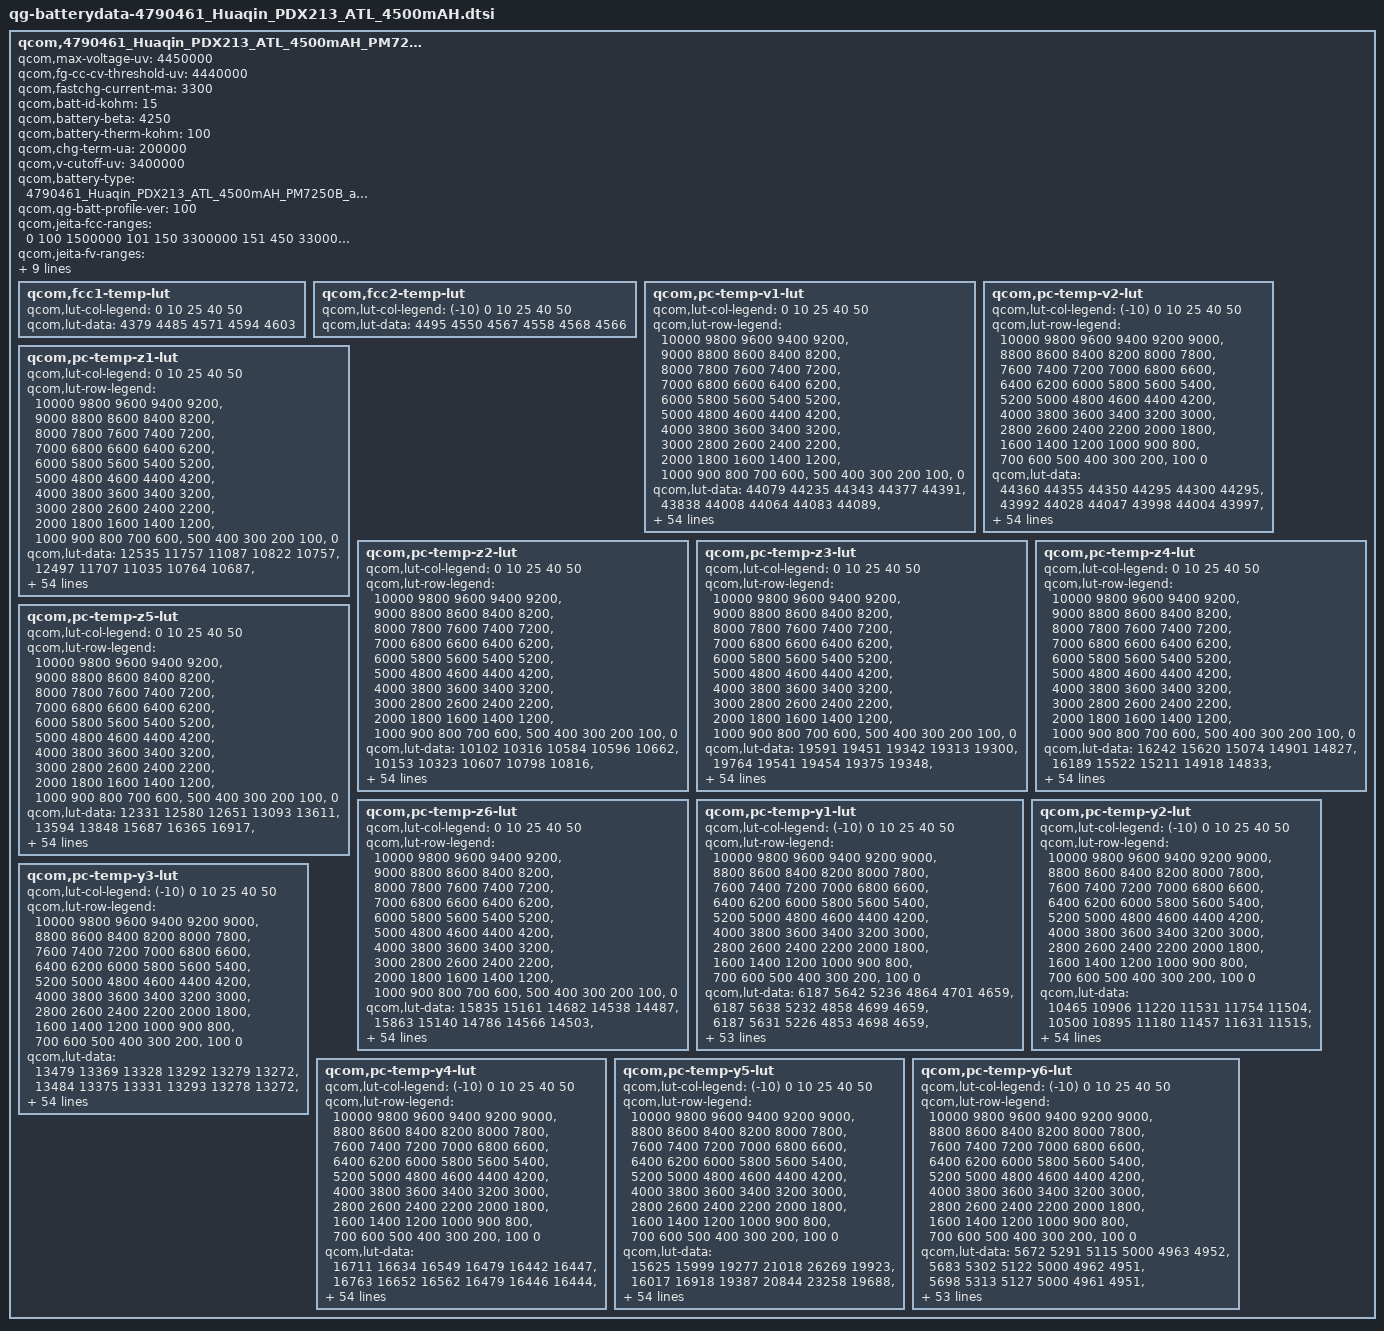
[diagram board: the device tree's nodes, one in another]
qcom,4790461_Huaqin_PDX213_ATL_4500mAH_PM7250B {
	/* 4790461_Huaqin_PDX213_ATL_4500mAH_PM7250B_averaged_MasterSlave_Sep18th2020 */
	qcom,max-voltage-uv = <4450000>;
	qcom,fg-cc-cv-threshold-uv = <4440000>;
	qcom,fastchg-current-ma = <3300>;
	qcom,batt-id-kohm = <15>;
	qcom,battery-beta = <4250>;
	qcom,battery-therm-kohm = <100>;
	qcom,chg-term-ua = <200000>;
	qcom,v-cutoff-uv = <3400000>;
	qcom,battery-type = "4790461_Huaqin_PDX213_ATL_4500mAH_PM7250B_averaged_MasterSlave_Sep18th2020";
	qcom,qg-batt-profile-ver = <100>;

	qcom,jeita-fcc-ranges = <0  100  1500000
				101 150  3300000
				151 450  3300000
				451 550  1000000>;

	qcom,jeita-fv-ranges = <0   100  4400000
				101 150  4400000
				151 450  4450000
				451 550  4100000>;

	qcom,step-chg-ranges = <3500000  4000000  3300000
				4000001  4100000  3300000
				4100001  4450000  1500000>;

	qcom,ocv-based-step-chg;

	/* COOL = 0 degc, WARM = 55 degC */
	qcom,jeita-soft-thresholds = <0x58CD 0x181D>;
	/* COLD = 0 degC, HOT = 55 degC*/
	qcom,jeita-hard-thresholds = <0x58CD 0x181D>;
	/* COOL hys = 5 degC, WARM hys = 50 degC */
	qcom,jeita-soft-hys-thresholds = <0x5314 0x1C22>;
	qcom,jeita-soft-fcc-ua = <1500000 900000>;
	qcom,jeita-soft-fv-uv = <4400000 4100000>;

	qcom,fcc1-temp-lut {
		qcom,lut-col-legend = <0 10 25 40 50>;
		qcom,lut-data = <4379 4485 4571 4594 4603>;
	};

	qcom,fcc2-temp-lut {
		qcom,lut-col-legend = <(-10) 0 10 25 40 50>;
		qcom,lut-data = <4495 4550 4567 4558 4568 4566>;
	};

	qcom,pc-temp-v1-lut {
		qcom,lut-col-legend = <0 10 25 40 50>;
		qcom,lut-row-legend = <10000 9800 9600 9400 9200>,
			<9000 8800 8600 8400 8200>,
			<8000 7800 7600 7400 7200>,
			<7000 6800 6600 6400 6200>,
			<6000 5800 5600 5400 5200>,
			<5000 4800 4600 4400 4200>,
			<4000 3800 3600 3400 3200>,
			<3000 2800 2600 2400 2200>,
			<2000 1800 1600 1400 1200>,
			<1000 900 800 700 600>,
			<500 400 300 200 100>,
			<0>;
		qcom,lut-data = <44079 44235 44343 44377 44391>,
			<43838 44008 44064 44083 44089>,
			<43608 43779 43841 43852 43856>,
			<43384 43552 43628 43640 43643>,
			<43154 43325 43403 43420 43425>,
			<42913 43092 43173 43195 43205>,
			<42669 42850 42937 42965 42978>,
			<42431 42604 42696 42726 42740>,
			<42195 42361 42451 42483 42497>,
			<41963 42118 42207 42240 42255>,
			<41733 41880 41963 41998 42016>,
			<41508 41648 41724 41759 41779>,
			<41291 41422 41489 41523 41545>,
			<41085 41203 41259 41291 41315>,
			<40880 40989 41038 41069 41091>,
			<40673 40781 40826 40854 40873>,
			<40468 40576 40621 40646 40663>,
			<40281 40380 40422 40444 40461>,
			<40107 40201 40233 40252 40268>,
			<39943 40039 40063 40076 40090>,
			<39787 39871 39897 39909 39921>,
			<39638 39698 39705 39714 39730>,
			<39477 39513 39479 39467 39491>,
			<39291 39285 39258 39234 39261>,
			<39104 39001 39045 39051 39077>,
			<38934 38801 38856 38895 38918>,
			<38773 38709 38736 38768 38783>,
			<38653 38643 38651 38665 38667>,
			<38572 38573 38570 38569 38562>,
			<38510 38504 38488 38472 38462>,
			<38456 38439 38411 38381 38371>,
			<38410 38373 38338 38301 38288>,
			<38367 38312 38268 38229 38214>,
			<38322 38259 38207 38164 38144>,
			<38277 38213 38158 38106 38081>,
			<38239 38170 38113 38052 38020>,
			<38207 38133 38068 37997 37956>,
			<38171 38094 38024 37942 37889>,
			<38114 38036 37966 37876 37814>,
			<38033 37951 37883 37794 37727>,
			<37936 37849 37782 37696 37628>,
			<37812 37733 37667 37584 37512>,
			<37668 37595 37531 37452 37375>,
			<37499 37427 37368 37290 37215>,
			<37334 37257 37206 37136 37066>,
			<37226 37140 37088 37028 36968>,
			<37180 37104 37060 37001 36942>,
			<37145 37084 37039 36987 36925>,
			<37112 37064 37023 36969 36908>,
			<37077 37034 36995 36940 36876>,
			<36993 36927 36856 36772 36681>,
			<36637 36528 36456 36361 36265>,
			<36082 35960 35893 35797 35699>,
			<35317 35170 35126 35028 34929>,
			<33982 33856 33940 33843 33745>,
			<30000 30000 30000 30000 30000>;
	};

	qcom,pc-temp-v2-lut {
		qcom,lut-col-legend = <(-10) 0 10 25 40 50>;
		qcom,lut-row-legend = <10000 9800 9600 9400 9200 9000>,
			<8800 8600 8400 8200 8000 7800>,
			<7600 7400 7200 7000 6800 6600>,
			<6400 6200 6000 5800 5600 5400>,
			<5200 5000 4800 4600 4400 4200>,
			<4000 3800 3600 3400 3200 3000>,
			<2800 2600 2400 2200 2000 1800>,
			<1600 1400 1200 1000 900 800>,
			<700 600 500 400 300 200>,
			<100 0>;
		qcom,lut-data = <44360 44355 44350 44295 44300 44295>,
			<43992 44028 44047 43998 44004 43997>,
			<43666 43732 43770 43724 43732 43724>,
			<43391 43476 43523 43476 43485 43477>,
			<43159 43256 43306 43255 43265 43259>,
			<42933 43033 43085 43031 43042 43038>,
			<42696 42792 42846 42792 42807 42803>,
			<42458 42546 42602 42549 42568 42565>,
			<42221 42301 42359 42307 42328 42325>,
			<41984 42054 42116 42065 42086 42083>,
			<41739 41816 41875 41826 41847 41845>,
			<41459 41587 41635 41589 41610 41610>,
			<41179 41364 41400 41358 41378 41380>,
			<40977 41149 41173 41131 41150 41153>,
			<40839 40939 40953 40911 40928 40932>,
			<40672 40726 40742 40698 40714 40717>,
			<40353 40509 40543 40491 40508 40510>,
			<39967 40283 40344 40292 40309 40309>,
			<39711 40032 40130 40109 40122 40122>,
			<39537 39758 39906 39935 39942 39943>,
			<39369 39513 39676 39742 39756 39760>,
			<39175 39302 39427 39509 39561 39571>,
			<38980 39110 39194 39273 39359 39375>,
			<38791 38932 39002 39061 39135 39151>,
			<38604 38768 38834 38862 38904 38915>,
			<38442 38619 38685 38704 38733 38742>,
			<38310 38485 38553 38578 38609 38617>,
			<38199 38359 38435 38468 38502 38510>,
			<38118 38230 38324 38364 38399 38407>,
			<38058 38103 38221 38266 38303 38312>,
			<38003 38011 38130 38178 38216 38224>,
			<37948 37943 38047 38098 38138 38144>,
			<37894 37889 37970 38024 38065 38069>,
			<37836 37845 37889 37959 38000 38002>,
			<37777 37809 37815 37900 37937 37937>,
			<37714 37771 37765 37839 37860 37850>,
			<37646 37733 37732 37776 37768 37733>,
			<37574 37690 37694 37707 37671 37619>,
			<37495 37634 37644 37628 37575 37519>,
			<37408 37564 37582 37540 37477 37423>,
			<37317 37472 37496 37449 37384 37329>,
			<37223 37343 37378 37352 37290 37235>,
			<37131 37198 37245 37236 37175 37118>,
			<37045 37036 37092 37096 37037 36978>,
			<36956 36886 36920 36941 36893 36839>,
			<36868 36782 36830 36876 36849 36799>,
			<36815 36740 36805 36866 36840 36786>,
			<36762 36703 36776 36849 36823 36772>,
			<36706 36667 36732 36828 36799 36753>,
			<36650 36607 36659 36778 36753 36689>,
			<36574 36463 36454 36603 36520 36415>,
			<36418 36090 35998 36152 36036 35920>,
			<36067 35442 35321 35527 35397 35268>,
			<35446 34451 34375 34677 34510 34359>,
			<34469 32921 32908 33453 33255 33082>,
			<32805 30344 29538 29120 29530 29563>;
	};

	qcom,pc-temp-z1-lut {
		qcom,lut-col-legend = <0 10 25 40 50>;
		qcom,lut-row-legend = <10000 9800 9600 9400 9200>,
			<9000 8800 8600 8400 8200>,
			<8000 7800 7600 7400 7200>,
			<7000 6800 6600 6400 6200>,
			<6000 5800 5600 5400 5200>,
			<5000 4800 4600 4400 4200>,
			<4000 3800 3600 3400 3200>,
			<3000 2800 2600 2400 2200>,
			<2000 1800 1600 1400 1200>,
			<1000 900 800 700 600>,
			<500 400 300 200 100>,
			<0>;
		qcom,lut-data = <12535 11757 11087 10822 10757>,
			<12497 11707 11035 10764 10687>,
			<12461 11669 11014 10752 10680>,
			<12419 11646 11001 10741 10673>,
			<12384 11626 10990 10734 10670>,
			<12358 11604 10978 10728 10668>,
			<12336 11577 10968 10725 10667>,
			<12314 11550 10957 10722 10666>,
			<12294 11530 10949 10720 10666>,
			<12273 11513 10946 10719 10666>,
			<12251 11504 10944 10718 10665>,
			<12229 11500 10942 10718 10663>,
			<12213 11497 10939 10717 10662>,
			<12199 11494 10937 10716 10662>,
			<12186 11490 10937 10716 10662>,
			<12172 11487 10937 10716 10663>,
			<12158 11482 10937 10717 10663>,
			<12150 11478 10937 10717 10664>,
			<12143 11476 10938 10718 10665>,
			<12140 11477 10939 10718 10666>,
			<12144 11477 10940 10719 10668>,
			<12151 11482 10942 10720 10669>,
			<12153 11488 10946 10722 10666>,
			<12149 11493 10949 10723 10663>,
			<12145 11499 10954 10726 10666>,
			<12150 11505 10959 10730 10675>,
			<12172 11509 10963 10733 10679>,
			<12186 11513 10968 10736 10681>,
			<12189 11516 10972 10739 10682>,
			<12190 11524 10976 10742 10684>,
			<12191 11530 10981 10745 10687>,
			<12194 11535 10986 10748 10688>,
			<12196 11542 10991 10751 10690>,
			<12193 11545 10996 10754 10691>,
			<12191 11549 11000 10757 10693>,
			<12198 11555 11005 10760 10696>,
			<12229 11566 11011 10764 10699>,
			<12262 11582 11019 10767 10703>,
			<12285 11595 11026 10771 10706>,
			<12305 11607 11033 10775 10708>,
			<12320 11617 11040 10779 10709>,
			<12332 11626 11047 10781 10712>,
			<12342 11635 11054 10783 10715>,
			<12350 11647 11060 10785 10716>,
			<12385 11674 11069 10789 10718>,
			<12388 11670 11075 10793 10718>,
			<12393 11668 11076 10791 10718>,
			<12410 11675 11078 10792 10719>,
			<12394 11691 11078 10793 10721>,
			<12391 11683 11084 10795 10720>,
			<12392 11692 11092 10803 10726>,
			<12455 11739 11109 10817 10734>,
			<12466 11741 11129 10827 10744>,
			<12500 11781 11166 10845 10762>,
			<12500 11781 11166 10845 10762>,
			<12500 11781 11166 10845 10762>;
	};

	qcom,pc-temp-z2-lut {
		qcom,lut-col-legend = <0 10 25 40 50>;
		qcom,lut-row-legend = <10000 9800 9600 9400 9200>,
			<9000 8800 8600 8400 8200>,
			<8000 7800 7600 7400 7200>,
			<7000 6800 6600 6400 6200>,
			<6000 5800 5600 5400 5200>,
			<5000 4800 4600 4400 4200>,
			<4000 3800 3600 3400 3200>,
			<3000 2800 2600 2400 2200>,
			<2000 1800 1600 1400 1200>,
			<1000 900 800 700 600>,
			<500 400 300 200 100>,
			<0>;
		qcom,lut-data = <10102 10316 10584 10596 10662>,
			<10153 10323 10607 10798 10816>,
			<10147 10321 10596 10811 10867>,
			<10124 10305 10575 10765 10881>,
			<10111 10281 10535 10721 10856>,
			<10106 10258 10471 10666 10779>,
			<10103 10234 10442 10629 10732>,
			<10100 10216 10436 10623 10751>,
			<10097 10214 10434 10626 10780>,
			<10093 10215 10440 10637 10785>,
			<10090 10216 10457 10655 10780>,
			<10087 10238 10475 10669 10776>,
			<10089 10272 10496 10681 10757>,
			<10100 10293 10517 10691 10727>,
			<10116 10309 10530 10675 10724>,
			<10131 10324 10541 10619 10755>,
			<10149 10341 10554 10595 10775>,
			<10169 10359 10574 10621 10746>,
			<10196 10375 10589 10654 10712>,
			<10219 10390 10597 10669 10724>,
			<10227 10404 10607 10690 10764>,
			<10233 10417 10632 10736 10834>,
			<10241 10429 10696 10904 11049>,
			<10261 10444 10733 11029 11218>,
			<10285 10463 10689 10908 11148>,
			<10308 10472 10623 10691 10996>,
			<10334 10467 10617 10669 10972>,
			<10349 10461 10638 10825 11071>,
			<10356 10462 10663 10927 11141>,
			<10360 10475 10706 10905 11031>,
			<10362 10487 10745 10859 10844>,
			<10362 10495 10734 10816 10772>,
			<10363 10504 10690 10754 10736>,
			<10370 10511 10671 10728 10724>,
			<10381 10517 10673 10762 10779>,
			<10386 10522 10676 10824 10874>,
			<10388 10525 10691 10884 10964>,
			<10391 10529 10728 10953 11065>,
			<10397 10536 10763 11010 11135>,
			<10408 10554 10800 11058 11185>,
			<10418 10565 10828 11094 11214>,
			<10425 10562 10837 11119 11214>,
			<10436 10559 10841 11136 11211>,
			<10468 10571 10845 11126 11217>,
			<10739 10711 10885 11102 11194>,
			<10523 10840 10940 11102 11130>,
			<10501 10833 10927 11050 11135>,
			<10466 10948 10907 11008 11070>,
			<10419 11251 10875 11035 11102>,
			<10368 11339 10875 11033 11215>,
			<10359 11253 11018 11086 10969>,
			<10260 11172 11141 10827 10769>,
			<10039 11005 11032 10734 10689>,
			<9912 10833 11008 10638 10616>,
			<9912 10833 11008 10638 10616>,
			<9912 10833 11008 10638 10616>;
	};

	qcom,pc-temp-z3-lut {
		qcom,lut-col-legend = <0 10 25 40 50>;
		qcom,lut-row-legend = <10000 9800 9600 9400 9200>,
			<9000 8800 8600 8400 8200>,
			<8000 7800 7600 7400 7200>,
			<7000 6800 6600 6400 6200>,
			<6000 5800 5600 5400 5200>,
			<5000 4800 4600 4400 4200>,
			<4000 3800 3600 3400 3200>,
			<3000 2800 2600 2400 2200>,
			<2000 1800 1600 1400 1200>,
			<1000 900 800 700 600>,
			<500 400 300 200 100>,
			<0>;
		qcom,lut-data = <19591 19451 19342 19313 19300>,
			<19764 19541 19454 19375 19348>,
			<19815 19603 19479 19397 19370>,
			<19841 19626 19493 19408 19381>,
			<19852 19638 19501 19416 19386>,
			<19856 19642 19505 19422 19389>,
			<19859 19641 19506 19425 19390>,
			<19854 19640 19495 19418 19389>,
			<19831 19637 19481 19407 19385>,
			<19815 19630 19470 19400 19381>,
			<19811 19621 19460 19394 19374>,
			<19808 19605 19453 19389 19367>,
			<19800 19588 19448 19385 19359>,
			<19781 19578 19443 19380 19351>,
			<19766 19572 19434 19371 19346>,
			<19763 19566 19424 19359 19342>,
			<19761 19558 19420 19353 19340>,
			<19754 19552 19418 19351 19335>,
			<19726 19548 19416 19350 19329>,
			<19703 19546 19413 19348 19325>,
			<19705 19544 19409 19345 19321>,
			<19715 19545 19412 19347 19321>,
			<19722 19547 19430 19362 19333>,
			<19727 19554 19441 19374 19344>,
			<19730 19570 19435 19362 19334>,
			<19731 19579 19424 19339 19313>,
			<19732 19568 19414 19333 19312>,
			<19733 19553 19405 19333 19346>,
			<19728 19549 19401 19335 19371>,
			<19720 19548 19410 19355 19370>,
			<19712 19547 19424 19382 19368>,
			<19703 19552 19433 19385 19364>,
			<19698 19558 19440 19378 19353>,
			<19697 19558 19442 19370 19343>,
			<19696 19553 19435 19364 19335>,
			<19695 19548 19426 19358 19329>,
			<19690 19545 19421 19355 19328>,
			<19683 19542 19418 19351 19327>,
			<19677 19538 19414 19350 19327>,
			<19670 19534 19410 19350 19328>,
			<19661 19528 19407 19349 19329>,
			<19650 19522 19405 19349 19332>,
			<19636 19513 19403 19348 19337>,
			<19616 19503 19397 19347 19337>,
			<19544 19475 19385 19341 19332>,
			<19342 19447 19377 19334 19316>,
			<19332 19444 19372 19333 19313>,
			<19317 19411 19372 19323 19313>,
			<19314 19316 19365 19323 19310>,
			<19308 19302 19364 19319 19305>,
			<19306 19316 19353 19325 19329>,
			<19310 19342 19337 19341 19337>,
			<19318 19316 19349 19346 19338>,
			<19329 19321 19334 19351 19341>,
			<19329 19321 19334 19351 19341>,
			<19329 19321 19334 19351 19341>;
	};

	qcom,pc-temp-z4-lut {
		qcom,lut-col-legend = <0 10 25 40 50>;
		qcom,lut-row-legend = <10000 9800 9600 9400 9200>,
			<9000 8800 8600 8400 8200>,
			<8000 7800 7600 7400 7200>,
			<7000 6800 6600 6400 6200>,
			<6000 5800 5600 5400 5200>,
			<5000 4800 4600 4400 4200>,
			<4000 3800 3600 3400 3200>,
			<3000 2800 2600 2400 2200>,
			<2000 1800 1600 1400 1200>,
			<1000 900 800 700 600>,
			<500 400 300 200 100>,
			<0>;
		qcom,lut-data = <16242 15620 15074 14901 14827>,
			<16189 15522 15211 14918 14833>,
			<16038 15420 15123 14908 14838>,
			<15770 15309 15003 14858 14806>,
			<15555 15184 14935 14820 14779>,
			<15407 15081 14884 14789 14756>,
			<15287 15008 14843 14766 14737>,
			<15201 14949 14808 14751 14723>,
			<15134 14902 14782 14740 14713>,
			<15076 14863 14770 14731 14707>,
			<15018 14836 14762 14723 14703>,
			<14968 14817 14753 14716 14699>,
			<14932 14804 14742 14707 14696>,
			<14906 14794 14733 14699 14692>,
			<14883 14786 14728 14696 14689>,
			<14860 14781 14724 14694 14679>,
			<14839 14781 14719 14691 14672>,
			<14836 14780 14711 14683 14667>,
			<14846 14775 14705 14674 14662>,
			<14856 14756 14699 14667 14658>,
			<14842 14746 14694 14661 14653>,
			<14806 14748 14697 14663 14653>,
			<14793 14755 14717 14695 14682>,
			<14810 14780 14745 14738 14723>,
			<14837 14855 14797 14779 14760>,
			<14864 14897 14848 14816 14794>,
			<14896 14890 14853 14822 14795>,
			<14909 14875 14844 14809 14748>,
			<14906 14860 14832 14791 14705>,
			<14899 14842 14806 14752 14688>,
			<14890 14825 14775 14709 14678>,
			<14878 14808 14752 14693 14672>,
			<14865 14794 14732 14685 14667>,
			<14854 14785 14723 14681 14664>,
			<14845 14779 14722 14679 14663>,
			<14834 14774 14721 14678 14662>,
			<14823 14769 14721 14680 14664>,
			<14812 14764 14722 14686 14672>,
			<14801 14761 14723 14693 14678>,
			<14790 14760 14730 14701 14682>,
			<14779 14757 14737 14706 14684>,
			<14769 14745 14729 14701 14680>,
			<14757 14729 14715 14693 14671>,
			<14737 14717 14710 14693 14673>,
			<14732 14692 14698 14691 14673>,
			<14894 14678 14679 14676 14671>,
			<14901 14673 14671 14669 14666>,
			<14911 14695 14656 14660 14650>,
			<14910 14797 14647 14640 14631>,
			<14910 14807 14640 14636 14628>,
			<14908 14791 14667 14656 14633>,
			<14916 14774 14700 14650 14633>,
			<14918 14811 14687 14646 14633>,
			<14923 14813 14706 14643 14632>,
			<14923 14813 14706 14643 14632>,
			<14923 14813 14706 14643 14632>;
	};

	qcom,pc-temp-z5-lut {
		qcom,lut-col-legend = <0 10 25 40 50>;
		qcom,lut-row-legend = <10000 9800 9600 9400 9200>,
			<9000 8800 8600 8400 8200>,
			<8000 7800 7600 7400 7200>,
			<7000 6800 6600 6400 6200>,
			<6000 5800 5600 5400 5200>,
			<5000 4800 4600 4400 4200>,
			<4000 3800 3600 3400 3200>,
			<3000 2800 2600 2400 2200>,
			<2000 1800 1600 1400 1200>,
			<1000 900 800 700 600>,
			<500 400 300 200 100>,
			<0>;
		qcom,lut-data = <12331 12580 12651 13093 13611>,
			<13594 13848 15687 16365 16917>,
			<14157 14864 16591 17475 18465>,
			<14500 15548 17350 18370 19750>,
			<14891 16037 18038 19234 20605>,
			<15467 16549 18628 20124 21142>,
			<16037 17158 19041 20576 21708>,
			<16392 17808 19373 20631 22749>,
			<16628 18517 19567 20671 23790>,
			<16959 19304 19570 20724 23798>,
			<17822 19882 19543 20744 23094>,
			<18902 20198 19619 20796 22619>,
			<19513 20460 20245 21238 22209>,
			<19907 20818 20740 21703 21592>,
			<20399 21266 20585 21292 21443>,
			<22417 21690 20285 20013 21941>,
			<25449 22052 20351 19563 22420>,
			<26030 22422 21271 20361 22659>,
			<23582 22856 22338 21550 22626>,
			<21394 23455 23034 22508 22513>,
			<22630 24380 23837 23594 22750>,
			<26698 26541 27034 26374 24157>,
			<31065 29861 38416 36433 31204>,
			<36618 34092 45422 43803 36886>,
			<41118 40196 39780 36300 31013>,
			<42030 43147 30149 22108 19010>,
			<42390 37828 25138 17542 16237>,
			<42481 30124 21441 16349 18630>,
			<40584 28122 20092 15943 21400>,
			<37485 27534 20770 18306 23707>,
			<35457 27340 22216 22457 25672>,
			<33763 29263 25203 25015 26331>,
			<32948 32446 30735 26844 26411>,
			<33508 34172 33537 28432 26659>,
			<34544 35313 34255 30206 27669>,
			<34935 35954 34602 31637 28649>,
			<34666 36213 34587 31869 28708>,
			<34473 36336 34466 31207 28524>,
			<35062 36344 34091 30153 28170>,
			<36075 36230 31485 27716 26519>,
			<36297 35917 29124 25501 24947>,
			<34294 34604 28989 25050 25806>,
			<32586 33019 28981 24792 27660>,
			<31957 31873 27075 23746 26525>,
			<27022 33284 26353 22160 24312>,
			<12913 30733 28139 22324 19504>,
			<12654 29402 26855 22693 19341>,
			<12285 19693 29140 21575 21451>,
			<12187 12847 26569 25559 26451>,
			<12093 12439 27527 25743 26433>,
			<12091 12916 20918 20402 27946>,
			<12143 14011 15797 21937 28838>,
			<12123 12720 16665 22568 28628>,
			<12467 12880 14783 23835 29178>,
			<12467 12880 14783 23835 29178>,
			<12467 12880 14783 23835 29178>;
	};

	qcom,pc-temp-z6-lut {
		qcom,lut-col-legend = <0 10 25 40 50>;
		qcom,lut-row-legend = <10000 9800 9600 9400 9200>,
			<9000 8800 8600 8400 8200>,
			<8000 7800 7600 7400 7200>,
			<7000 6800 6600 6400 6200>,
			<6000 5800 5600 5400 5200>,
			<5000 4800 4600 4400 4200>,
			<4000 3800 3600 3400 3200>,
			<3000 2800 2600 2400 2200>,
			<2000 1800 1600 1400 1200>,
			<1000 900 800 700 600>,
			<500 400 300 200 100>,
			<0>;
		qcom,lut-data = <15835 15161 14682 14538 14487>,
			<15863 15140 14786 14566 14503>,
			<15817 15115 14754 14569 14511>,
			<15679 15079 14710 14555 14505>,
			<15563 15020 14684 14543 14498>,
			<15484 14965 14662 14533 14490>,
			<15415 14926 14641 14523 14482>,
			<15355 14892 14618 14512 14475>,
			<15300 14862 14599 14502 14469>,
			<15254 14837 14587 14494 14463>,
			<15216 14815 14578 14487 14458>,
			<15183 14796 14569 14481 14452>,
			<15153 14781 14562 14474 14447>,
			<15124 14770 14554 14468 14441>,
			<15101 14763 14547 14461 14435>,
			<15086 14757 14541 14454 14429>,
			<15075 14751 14535 14449 14424>,
			<15065 14746 14531 14444 14419>,
			<15056 14739 14527 14439 14414>,
			<15048 14731 14523 14435 14410>,
			<15041 14727 14519 14432 14405>,
			<15035 14729 14521 14433 14406>,
			<15034 14735 14540 14457 14426>,
			<15044 14751 14559 14481 14449>,
			<15061 14793 14578 14490 14458>,
			<15076 14816 14595 14496 14464>,
			<15091 14809 14595 14497 14465>,
			<15098 14797 14587 14492 14462>,
			<15095 14788 14580 14486 14458>,
			<15089 14780 14574 14482 14453>,
			<15083 14775 14569 14477 14447>,
			<15074 14772 14565 14472 14441>,
			<15068 14771 14562 14465 14434>,
			<15066 14768 14558 14460 14428>,
			<15065 14764 14554 14455 14423>,
			<15063 14761 14550 14451 14419>,
			<15060 14761 14549 14451 14419>,
			<15057 14760 14549 14453 14422>,
			<15058 14760 14549 14454 14425>,
			<15059 14762 14551 14458 14427>,
			<15060 14763 14553 14461 14429>,
			<15060 14759 14551 14459 14429>,
			<15059 14752 14545 14455 14428>,
			<15054 14748 14541 14455 14428>,
			<15024 14731 14531 14451 14426>,
			<15004 14716 14520 14441 14418>,
			<15003 14712 14515 14438 14414>,
			<15002 14706 14509 14429 14406>,
			<15001 14703 14501 14420 14397>,
			<15003 14704 14500 14417 14393>,
			<15013 14711 14508 14429 14408>,
			<15030 14725 14517 14438 14414>,
			<15049 14737 14523 14441 14418>,
			<15081 14757 14530 14446 14423>,
			<15081 14757 14530 14446 14423>,
			<15081 14757 14530 14446 14423>;
	};

	qcom,pc-temp-y1-lut {
		qcom,lut-col-legend = <(-10) 0 10 25 40 50>;
		qcom,lut-row-legend = <10000 9800 9600 9400 9200 9000>,
			<8800 8600 8400 8200 8000 7800>,
			<7600 7400 7200 7000 6800 6600>,
			<6400 6200 6000 5800 5600 5400>,
			<5200 5000 4800 4600 4400 4200>,
			<4000 3800 3600 3400 3200 3000>,
			<2800 2600 2400 2200 2000 1800>,
			<1600 1400 1200 1000 900 800>,
			<700 600 500 400 300 200>,
			<100 0>;
		qcom,lut-data = <6187 5642 5236 4864 4701 4659>,
			<6187 5638 5232 4858 4699 4659>,
			<6187 5631 5226 4853 4698 4659>,
			<6188 5621 5219 4848 4696 4658>,
			<6189 5614 5212 4843 4695 4658>,
			<6190 5611 5206 4839 4695 4658>,
			<6191 5611 5199 4836 4695 4657>,
			<6191 5610 5193 4834 4695 4656>,
			<6192 5608 5192 4831 4694 4656>,
			<6198 5601 5191 4828 4692 4657>,
			<6203 5598 5191 4826 4690 4657>,
			<6207 5606 5189 4825 4690 4656>,
			<6210 5614 5185 4824 4689 4655>,
			<6207 5612 5182 4824 4689 4656>,
			<6190 5599 5177 4823 4689 4658>,
			<6179 5592 5175 4822 4689 4658>,
			<6186 5601 5173 4822 4690 4657>,
			<6198 5613 5172 4821 4691 4656>,
			<6200 5614 5173 4822 4692 4657>,
			<6198 5615 5176 4824 4691 4659>,
			<6196 5614 5179 4826 4691 4659>,
			<6197 5612 5184 4827 4692 4658>,
			<6198 5610 5188 4829 4692 4657>,
			<6198 5612 5189 4832 4693 4658>,
			<6200 5618 5188 4835 4695 4660>,
			<6201 5621 5189 4838 4696 4661>,
			<6199 5619 5192 4841 4698 4664>,
			<6196 5617 5194 4843 4699 4665>,
			<6200 5624 5196 4847 4700 4665>,
			<6222 5638 5198 4850 4702 4666>,
			<6235 5641 5200 4854 4703 4666>,
			<6220 5626 5203 4857 4706 4668>,
			<6197 5614 5206 4860 4708 4670>,
			<6190 5623 5208 4863 4709 4671>,
			<6192 5640 5210 4867 4711 4673>,
			<6192 5643 5215 4870 4712 4675>,
			<6191 5636 5224 4874 4714 4676>,
			<6191 5630 5232 4876 4715 4677>,
			<6191 5633 5236 4879 4716 4677>,
			<6181 5637 5239 4882 4716 4676>,
			<6173 5636 5239 4883 4718 4677>,
			<6180 5625 5237 4885 4719 4679>,
			<6191 5629 5242 4888 4721 4680>,
			<6201 5650 5253 4892 4723 4681>,
			<6209 5644 5275 4898 4725 4682>,
			<6277 5681 5284 4906 4727 4683>,
			<6290 5673 5285 4908 4727 4685>,
			<6292 5667 5288 4909 4728 4686>,
			<6261 5678 5293 4913 4730 4685>,
			<6319 5697 5299 4916 4730 4686>,
			<6312 5712 5295 4917 4730 4687>,
			<6392 5746 5302 4923 4733 4689>,
			<6497 5809 5324 4943 4740 4695>,
			<6536 5863 5385 4965 4749 4704>,
			<6536 5863 5385 4965 4749 4704>,
			<6536 5863 5385 4965 4749 4704>;
	};

	qcom,pc-temp-y2-lut {
		qcom,lut-col-legend = <(-10) 0 10 25 40 50>;
		qcom,lut-row-legend = <10000 9800 9600 9400 9200 9000>,
			<8800 8600 8400 8200 8000 7800>,
			<7600 7400 7200 7000 6800 6600>,
			<6400 6200 6000 5800 5600 5400>,
			<5200 5000 4800 4600 4400 4200>,
			<4000 3800 3600 3400 3200 3000>,
			<2800 2600 2400 2200 2000 1800>,
			<1600 1400 1200 1000 900 800>,
			<700 600 500 400 300 200>,
			<100 0>;
		qcom,lut-data = <10465 10906 11220 11531 11754 11504>,
			<10500 10895 11180 11457 11631 11515>,
			<10539 10881 11139 11383 11492 11512>,
			<10577 10866 11099 11314 11363 11498>,
			<10609 10850 11059 11255 11269 11475>,
			<10630 10836 11020 11210 11236 11445>,
			<10642 10819 10975 11174 11263 11370>,
			<10650 10805 10936 11148 11297 11286>,
			<10649 10800 10921 11141 11290 11254>,
			<10635 10798 10911 11140 11248 11232>,
			<10626 10797 10908 11140 11226 11224>,
			<10695 10804 10915 11137 11224 11263>,
			<10804 10821 10926 11135 11223 11314>,
			<10822 10857 10938 11143 11231 11336>,
			<10808 10927 10956 11171 11258 11357>,
			<10798 10959 10981 11206 11287 11363>,
			<10811 10958 11041 11268 11314 11351>,
			<10838 10957 11106 11336 11349 11342>,
			<10864 10974 11147 11386 11407 11374>,
			<10895 11024 11179 11428 11493 11470>,
			<10911 11057 11188 11440 11584 11583>,
			<10909 11073 11184 11422 11704 11749>,
			<10904 11085 11181 11404 11783 11864>,
			<10894 11095 11197 11406 11732 11800>,
			<10866 11105 11234 11417 11611 11661>,
			<10815 11111 11260 11433 11557 11624>,
			<10462 11117 11277 11463 11537 11642>,
			<9936 11121 11291 11491 11528 11672>,
			<9781 11118 11307 11514 11568 11717>,
			<9745 11112 11320 11541 11659 11788>,
			<9723 11110 11323 11566 11745 11885>,
			<9707 11114 11318 11601 11836 12038>,
			<9696 11117 11313 11622 11901 12127>,
			<9687 11098 11312 11617 11940 12127>,
			<9681 11047 11312 11606 11968 12115>,
			<9676 11001 11304 11598 11963 12078>,
			<9673 10956 11284 11586 11896 11981>,
			<9670 10906 11260 11581 11846 11928>,
			<9668 10855 11231 11583 11789 11934>,
			<9667 10786 11193 11585 11726 11943>,
			<9665 10565 11134 11568 11728 11929>,
			<9664 9924 11050 11510 11756 11874>,
			<9663 9724 10979 11495 11755 11849>,
			<9662 9695 10892 11491 11718 11841>,
			<9661 9681 10787 11388 11672 11815>,
			<9660 9673 10688 11356 11635 11631>,
			<9659 9669 10645 11373 11539 11568>,
			<9658 9665 10559 11364 11500 11473>,
			<9656 9663 10329 11341 11452 11494>,
			<9654 9660 10089 11319 11499 11565>,
			<9652 9657 9747 11287 11435 11408>,
			<9649 9652 9690 11233 11355 11306>,
			<9648 9649 9663 11090 11268 11267>,
			<9647 9648 9654 10970 11146 11125>,
			<9647 9648 9654 10970 11146 11125>,
			<9647 9648 9654 10970 11146 11125>;
	};

	qcom,pc-temp-y3-lut {
		qcom,lut-col-legend = <(-10) 0 10 25 40 50>;
		qcom,lut-row-legend = <10000 9800 9600 9400 9200 9000>,
			<8800 8600 8400 8200 8000 7800>,
			<7600 7400 7200 7000 6800 6600>,
			<6400 6200 6000 5800 5600 5400>,
			<5200 5000 4800 4600 4400 4200>,
			<4000 3800 3600 3400 3200 3000>,
			<2800 2600 2400 2200 2000 1800>,
			<1600 1400 1200 1000 900 800>,
			<700 600 500 400 300 200>,
			<100 0>;
		qcom,lut-data = <13479 13369 13328 13292 13279 13272>,
			<13484 13375 13331 13293 13278 13272>,
			<13491 13383 13334 13294 13278 13272>,
			<13499 13392 13337 13295 13278 13272>,
			<13506 13399 13340 13295 13278 13273>,
			<13509 13403 13342 13295 13278 13273>,
			<13511 13404 13343 13295 13279 13274>,
			<13512 13405 13344 13296 13281 13275>,
			<13512 13405 13346 13297 13283 13276>,
			<13508 13404 13348 13300 13286 13277>,
			<13502 13402 13348 13302 13287 13278>,
			<13493 13401 13346 13302 13288 13281>,
			<13483 13400 13343 13302 13289 13283>,
			<13475 13400 13343 13303 13289 13284>,
			<13468 13402 13343 13307 13288 13285>,
			<13461 13403 13344 13309 13289 13285>,
			<13453 13398 13344 13307 13291 13284>,
			<13444 13390 13345 13306 13293 13284>,
			<13440 13384 13344 13304 13293 13284>,
			<13437 13379 13343 13304 13292 13286>,
			<13434 13374 13341 13303 13291 13286>,
			<13428 13370 13335 13301 13290 13285>,
			<13420 13366 13329 13300 13288 13284>,
			<13414 13362 13325 13297 13284 13280>,
			<13410 13359 13322 13293 13279 13273>,
			<13404 13356 13321 13291 13277 13272>,
			<13390 13354 13320 13291 13277 13272>,
			<13372 13351 13319 13291 13278 13273>,
			<13371 13347 13318 13291 13277 13273>,
			<13385 13340 13316 13290 13275 13273>,
			<13402 13336 13316 13289 13275 13273>,
			<13417 13334 13317 13290 13275 13273>,
			<13434 13332 13317 13290 13276 13273>,
			<13454 13336 13315 13290 13278 13274>,
			<13481 13344 13313 13290 13279 13274>,
			<13513 13351 13313 13290 13279 13274>,
			<13550 13357 13317 13291 13278 13272>,
			<13595 13362 13320 13291 13277 13271>,
			<13645 13366 13323 13290 13276 13272>,
			<13703 13370 13325 13289 13275 13272>,
			<13766 13378 13326 13289 13275 13273>,
			<13833 13394 13328 13289 13276 13274>,
			<13908 13413 13329 13289 13277 13275>,
			<13996 13438 13331 13290 13277 13275>,
			<14100 13475 13331 13289 13273 13270>,
			<14159 13512 13332 13289 13276 13274>,
			<14238 13568 13339 13294 13281 13275>,
			<14355 13650 13347 13296 13283 13281>,
			<14511 13774 13354 13302 13287 13284>,
			<14795 13956 13371 13307 13291 13284>,
			<15632 14286 13407 13307 13286 13280>,
			<17658 15259 13490 13304 13284 13280>,
			<23753 19034 13756 13309 13286 13281>,
			<47602 37611 15114 13318 13291 13285>,
			<47602 37611 15114 13318 13291 13285>,
			<47602 37611 15114 13318 13291 13285>;
	};

	qcom,pc-temp-y4-lut {
		qcom,lut-col-legend = <(-10) 0 10 25 40 50>;
		qcom,lut-row-legend = <10000 9800 9600 9400 9200 9000>,
			<8800 8600 8400 8200 8000 7800>,
			<7600 7400 7200 7000 6800 6600>,
			<6400 6200 6000 5800 5600 5400>,
			<5200 5000 4800 4600 4400 4200>,
			<4000 3800 3600 3400 3200 3000>,
			<2800 2600 2400 2200 2000 1800>,
			<1600 1400 1200 1000 900 800>,
			<700 600 500 400 300 200>,
			<100 0>;
		qcom,lut-data = <16711 16634 16549 16479 16442 16447>,
			<16763 16652 16562 16479 16446 16444>,
			<16842 16687 16577 16480 16448 16443>,
			<16929 16727 16590 16481 16450 16442>,
			<17001 16760 16600 16482 16451 16441>,
			<17037 16773 16604 16483 16451 16441>,
			<17045 16773 16601 16486 16451 16442>,
			<17050 16773 16597 16489 16450 16443>,
			<17056 16775 16597 16490 16450 16444>,
			<17065 16780 16598 16490 16451 16447>,
			<17070 16788 16600 16491 16453 16448>,
			<17057 16802 16611 16499 16457 16449>,
			<17037 16821 16629 16509 16463 16449>,
			<17050 16841 16644 16516 16470 16451>,
			<17140 16863 16660 16521 16478 16456>,
			<17199 16873 16679 16529 16485 16463>,
			<17083 16875 16712 16548 16490 16471>,
			<16897 16876 16736 16572 16497 16479>,
			<16850 16849 16730 16601 16511 16488>,
			<16845 16765 16705 16634 16534 16499>,
			<16838 16708 16674 16643 16547 16510>,
			<16813 16681 16625 16609 16555 16526>,
			<16772 16661 16580 16561 16559 16536>,
			<16727 16642 16558 16522 16530 16512>,
			<16666 16626 16543 16486 16470 16461>,
			<16632 16612 16535 16476 16453 16446>,
			<16661 16600 16531 16477 16455 16447>,
			<16710 16589 16529 16478 16457 16449>,
			<16723 16569 16529 16482 16463 16453>,
			<16726 16545 16530 16490 16475 16462>,
			<16728 16539 16530 16498 16485 16470>,
			<16734 16547 16529 16505 16496 16479>,
			<16742 16558 16527 16513 16504 16488>,
			<16747 16567 16521 16524 16512 16498>,
			<16753 16577 16513 16534 16517 16506>,
			<16757 16592 16514 16536 16516 16504>,
			<16759 16616 16529 16530 16501 16483>,
			<16760 16641 16547 16521 16487 16468>,
			<16760 16661 16567 16505 16474 16462>,
			<16757 16679 16584 16487 16465 16458>,
			<16756 16693 16587 16485 16465 16458>,
			<16760 16705 16587 16489 16466 16458>,
			<16768 16701 16590 16492 16465 16457>,
			<16778 16677 16592 16494 16462 16452>,
			<16791 16658 16563 16474 16445 16436>,
			<16761 16650 16557 16472 16448 16441>,
			<16764 16660 16572 16480 16453 16449>,
			<16774 16679 16594 16496 16463 16453>,
			<16793 16704 16635 16511 16479 16486>,
			<16828 16745 16687 16535 16521 16532>,
			<16999 16781 16727 16536 16495 16477>,
			<17362 16870 16722 16506 16454 16447>,
			<18460 17894 16766 16518 16457 16453>,
			<25601 29728 17319 16556 16482 16476>,
			<25601 29728 17319 16556 16482 16476>,
			<25601 29728 17319 16556 16482 16476>;
	};

	qcom,pc-temp-y5-lut {
		qcom,lut-col-legend = <(-10) 0 10 25 40 50>;
		qcom,lut-row-legend = <10000 9800 9600 9400 9200 9000>,
			<8800 8600 8400 8200 8000 7800>,
			<7600 7400 7200 7000 6800 6600>,
			<6400 6200 6000 5800 5600 5400>,
			<5200 5000 4800 4600 4400 4200>,
			<4000 3800 3600 3400 3200 3000>,
			<2800 2600 2400 2200 2000 1800>,
			<1600 1400 1200 1000 900 800>,
			<700 600 500 400 300 200>,
			<100 0>;
		qcom,lut-data = <15625 15999 19277 21018 26269 19923>,
			<16017 16918 19387 20844 23258 19688>,
			<16429 17624 19336 20052 20610 19348>,
			<16849 18121 19182 18971 18495 18966>,
			<17264 18413 18985 17921 17083 18611>,
			<17662 18502 18802 17227 16548 18347>,
			<18134 18332 18459 16495 17129 18143>,
			<18548 18003 18011 15800 17993 17923>,
			<18629 17632 17702 15806 18279 17610>,
			<18596 17137 17446 16198 18795 17177>,
			<18518 16921 17068 16301 18849 17024>,
			<17751 17010 16109 15681 18198 18132>,
			<16625 17185 15200 15022 17329 19424>,
			<16859 17374 15096 15023 16492 19274>,
			<19328 17632 15230 15236 15612 18286>,
			<20963 18107 15498 15310 15325 17306>,
			<20356 20259 16395 14828 15530 16294>,
			<19388 22433 17778 14309 15740 15547>,
			<19498 22463 19772 14485 15480 15377>,
			<21139 22021 22323 15314 14788 15289>,
			<22332 21855 23091 16666 14814 15434>,
			<22514 22176 22741 20422 17925 17434>,
			<22583 22545 22308 23538 20681 19330>,
			<22477 22623 21980 23021 20568 19318>,
			<22107 22643 21649 21515 20050 18874>,
			<21514 22748 21537 20906 19660 18791>,
			<18244 23130 21743 20840 19414 18728>,
			<13516 23437 21891 20761 19082 18515>,
			<12551 22447 21694 20239 17967 17937>,
			<12704 19911 21454 19479 16427 17119>,
			<12876 18092 21769 19327 16125 16885>,
			<13044 16692 23767 19556 16455 16803>,
			<13232 15922 25033 19871 16973 16768>,
			<13372 16522 23455 20269 18057 17057>,
			<13578 17994 21074 20891 19477 17594>,
			<13759 19138 20827 21771 20051 17903>,
			<13981 20135 21587 23225 20130 18102>,
			<14239 20672 22029 24053 20035 18327>,
			<14279 20700 21663 23362 19525 18756>,
			<14159 20692 20938 21904 18969 19338>,
			<13977 20143 20148 20594 19004 20121>,
			<13595 17332 19208 19336 19166 21367>,
			<13207 15721 18602 18878 19104 22053>,
			<13203 14921 18309 18707 19019 22135>,
			<13137 14240 18311 20380 19257 20607>,
			<13470 13850 17926 18749 17963 18368>,
			<13446 13629 18048 19888 18908 16988>,
			<13484 13628 17522 17982 17278 20228>,
			<13431 13910 15893 18169 19203 22254>,
			<13382 13965 15082 18532 20814 19006>,
			<12535 14004 14177 19563 19096 19630>,
			<11342 12900 14348 20445 21537 23296>,
			<9900 10316 13859 21319 22893 22877>,
			<9079 9055 11936 22217 25874 26587>,
			<9079 9055 11936 22217 25874 26587>,
			<9079 9055 11936 22217 25874 26587>;
	};

	qcom,pc-temp-y6-lut {
		qcom,lut-col-legend = <(-10) 0 10 25 40 50>;
		qcom,lut-row-legend = <10000 9800 9600 9400 9200 9000>,
			<8800 8600 8400 8200 8000 7800>,
			<7600 7400 7200 7000 6800 6600>,
			<6400 6200 6000 5800 5600 5400>,
			<5200 5000 4800 4600 4400 4200>,
			<4000 3800 3600 3400 3200 3000>,
			<2800 2600 2400 2200 2000 1800>,
			<1600 1400 1200 1000 900 800>,
			<700 600 500 400 300 200>,
			<100 0>;
		qcom,lut-data = <5672 5291 5115 5000 4963 4952>,
			<5683 5302 5122 5000 4962 4951>,
			<5698 5313 5127 5000 4961 4951>,
			<5713 5323 5130 5000 4961 4951>,
			<5724 5330 5132 5001 4962 4952>,
			<5728 5333 5133 5001 4962 4953>,
			<5727 5331 5131 5001 4963 4953>,
			<5724 5328 5128 5002 4965 4954>,
			<5722 5325 5128 5003 4966 4955>,
			<5718 5322 5127 5005 4968 4957>,
			<5713 5321 5127 5007 4970 4958>,
			<5701 5323 5128 5009 4971 4960>,
			<5686 5325 5130 5011 4973 4962>,
			<5687 5329 5132 5014 4975 4964>,
			<5711 5335 5136 5018 4977 4965>,
			<5727 5338 5141 5021 4980 4967>,
			<5693 5336 5150 5026 4983 4969>,
			<5638 5332 5157 5031 4986 4971>,
			<5626 5320 5155 5038 4991 4974>,
			<5626 5294 5147 5047 4996 4978>,
			<5626 5275 5136 5049 4999 4982>,
			<5621 5266 5118 5039 4999 4985>,
			<5613 5259 5101 5024 4999 4987>,
			<5606 5253 5093 5010 4989 4978>,
			<5598 5249 5088 4997 4968 4958>,
			<5594 5246 5085 4994 4962 4952>,
			<5597 5245 5085 4994 4962 4953>,
			<5603 5243 5084 4995 4963 4954>,
			<5614 5239 5084 4996 4964 4955>,
			<5635 5233 5085 4998 4967 4958>,
			<5661 5232 5086 5000 4969 4960>,
			<5688 5238 5088 5003 4973 4963>,
			<5717 5248 5089 5006 4976 4966>,
			<5750 5262 5088 5010 4980 4969>,
			<5786 5281 5087 5013 4983 4972>,
			<5826 5303 5088 5014 4982 4971>,
			<5869 5331 5097 5013 4977 4964>,
			<5915 5362 5108 5012 4973 4959>,
			<5964 5395 5119 5007 4968 4958>,
			<6015 5430 5131 5002 4965 4957>,
			<6071 5464 5141 5001 4965 4957>,
			<6131 5495 5150 5003 4967 4959>,
			<6199 5531 5164 5005 4967 4959>,
			<6281 5573 5181 5007 4967 4958>,
			<6382 5627 5184 5002 4959 4950>,
			<6448 5688 5196 5001 4963 4954>,
			<6517 5753 5225 5008 4968 4958>,
			<6624 5841 5260 5015 4972 4963>,
			<6770 5966 5308 5024 4979 4975>,
			<7050 6146 5372 5035 4995 4988>,
			<7832 6462 5452 5036 4983 4970>,
			<9544 7339 5576 5027 4970 4961>,
			<14298 10515 5896 5038 4974 4965>,
			<32109 26369 7225 5061 4985 4975>,
			<32109 26369 7225 5061 4985 4975>,
			<32109 26369 7225 5061 4985 4975>;
	};

};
